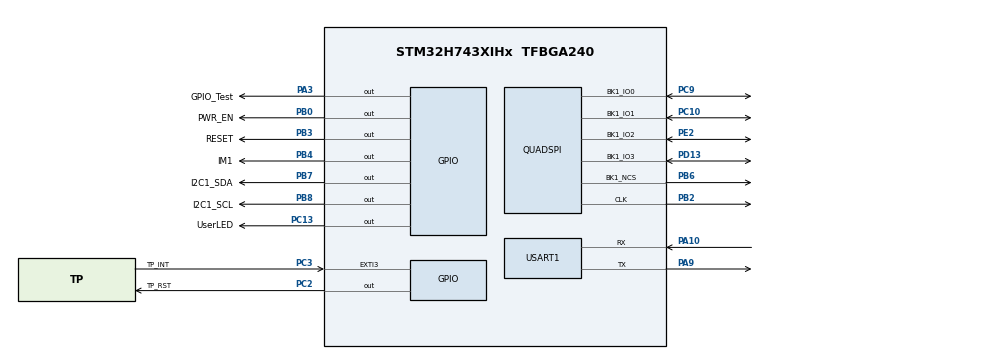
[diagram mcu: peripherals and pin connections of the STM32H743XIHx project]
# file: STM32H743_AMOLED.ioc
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CORTEX_M7.default_mode_Activation=0
Mcu.Family=STM32H7
Mcu.Name=STM32H743XIHx
Mcu.Package=TFBGA240
NVIC.PriorityGroup=NVIC_PRIORITYGROUP_4
NVIC.QUADSPI_IRQn=true\:0\:0\:false\:false\:true\:true\:true\:true
PA10.GPIO_Speed=GPIO_SPEED_FREQ_VERY_HIGH
PA10.Mode=Asynchronous
PA10.Signal=USART1_RX
PA13\ (JTMS/SWDIO).Mode=Serial_Wire
PA13\ (JTMS/SWDIO).Signal=DEBUG_JTMS-SWDIO
PA14\ (JTCK/SWCLK).Mode=Serial_Wire
PA14\ (JTCK/SWCLK).Signal=DEBUG_JTCK-SWCLK
PA3.GPIO_Label=GPIO_Test
PA3.GPIO_PuPd=GPIO_PULLDOWN
PA3.GPIO_Speed=GPIO_SPEED_FREQ_VERY_HIGH
PA3.PinState=GPIO_PIN_RESET
PA3.Signal=GPIO_Output
PA9.GPIO_Speed=GPIO_SPEED_FREQ_VERY_HIGH
PA9.Mode=Asynchronous
PA9.Signal=USART1_TX
PB0.GPIO_Label=PWR_EN
PB0.GPIO_PuPd=GPIO_PULLDOWN
PB0.GPIO_Speed=GPIO_SPEED_FREQ_VERY_HIGH
PB0.PinState=GPIO_PIN_RESET
PB0.Signal=GPIO_Output
PB2.GPIO_PuPd=GPIO_PULLUP
PB2.GPIO_Speed=GPIO_SPEED_FREQ_VERY_HIGH
PB2.Mode=Single Bank 1
PB2.Signal=QUADSPI_CLK
PB3\ (JTDO/TRACESWO).GPIO_Label=RESET
PB3\ (JTDO/TRACESWO).GPIO_PuPd=GPIO_PULLDOWN
PB3\ (JTDO/TRACESWO).GPIO_Speed=GPIO_SPEED_FREQ_VERY_HIGH
PB3\ (JTDO/TRACESWO).PinState=GPIO_PIN_RESET
PB3\ (JTDO/TRACESWO).Signal=GPIO_Output
PB4\ (NJTRST).GPIO_Label=IM1
PB4\ (NJTRST).GPIO_PuPd=GPIO_PULLUP
PB4\ (NJTRST).GPIO_Speed=GPIO_SPEED_FREQ_VERY_HIGH
PB4\ (NJTRST).PinState=GPIO_PIN_SET
PB4\ (NJTRST).Signal=GPIO_Output
PB6.GPIO_PuPd=GPIO_PULLUP
PB6.GPIO_Speed=GPIO_SPEED_FREQ_VERY_HIGH
PB6.Mode=Single Bank 1
PB6.Signal=QUADSPI_BK1_NCS
PB7.GPIO_FM7=SYSCFG_PMCR_I2C_PB7_FMP
PB7.GPIO_Label=I2C1_SDA
PB7.GPIO_ModeDefaultOutputPP=GPIO_MODE_OUTPUT_OD
PB7.GPIO_PuPd=GPIO_NOPULL
PB7.GPIO_Speed=GPIO_SPEED_FREQ_VERY_HIGH
PB7.PinState=GPIO_PIN_RESET
PB7.Signal=GPIO_Output
PB8.GPIO_FM8=SYSCFG_PMCR_I2C_PB8_FMP
PB8.GPIO_Label=I2C1_SCL
PB8.GPIO_ModeDefaultOutputPP=GPIO_MODE_OUTPUT_OD
PB8.GPIO_PuPd=GPIO_NOPULL
PB8.GPIO_Speed=GPIO_SPEED_FREQ_VERY_HIGH
PB8.PinState=GPIO_PIN_RESET
PB8.Signal=GPIO_Output
PC10.GPIO_Speed=GPIO_SPEED_FREQ_VERY_HIGH
PC10.Mode=Single Bank 1
PC10.Signal=QUADSPI_BK1_IO1
PC13.GPIO_Label=UserLED
PC13.GPIO_PuPd=GPIO_PULLUP
PC13.GPIO_Speed=GPIO_SPEED_FREQ_LOW
PC13.PinState=GPIO_PIN_SET
PC13.Signal=GPIO_Output
PC14-OSC32_IN\ (OSC32_IN).Mode=LSE-External-Oscillator
PC14-OSC32_IN\ (OSC32_IN).Signal=RCC_OSC32_IN
PC15-OSC32_OUT\ (OSC32_OUT).Mode=LSE-External-Oscillator
PC15-OSC32_OUT\ (OSC32_OUT).Signal=RCC_OSC32_OUT
PC2.GPIO_Label=TP_RST
PC2.GPIO_PuPd=GPIO_PULLDOWN
PC2.GPIO_Speed=GPIO_SPEED_FREQ_VERY_HIGH
PC2.PinState=GPIO_PIN_RESET
PC2.Signal=GPIO_Output
PC3.GPIO_Label=TP_INT
PC3.GPIO_ModeDefaultEXTI=GPIO_MODE_IT_FALLING
PC3.GPIO_PuPd=GPIO_PULLUP
PC3.Signal=GPXTI3
PC9.GPIO_Speed=GPIO_SPEED_FREQ_VERY_HIGH
PC9.Mode=Single Bank 1
PC9.Signal=QUADSPI_BK1_IO0
PD13.GPIO_Speed=GPIO_SPEED_FREQ_VERY_HIGH
PD13.Mode=Single Bank 1
PD13.Signal=QUADSPI_BK1_IO3
PE2.GPIO_Speed=GPIO_SPEED_FREQ_VERY_HIGH
PE2.Mode=Single Bank 1
PE2.Signal=QUADSPI_BK1_IO2
PH0-OSC_IN\ (PH0).Mode=HSE-External-Oscillator
PH0-OSC_IN\ (PH0).Signal=RCC_OSC_IN
PH1-OSC_OUT\ (PH1).Mode=HSE-External-Oscillator
PH1-OSC_OUT\ (PH1).Signal=RCC_OSC_OUT
ProjectManager.HeapSize=0x200
ProjectManager.StackSize=0x400
ProjectManager.TargetToolchain=MDK-ARM V5.32
QUADSPI.ClockPrescaler=4
QUADSPI.FifoThreshold=32
QUADSPI.FlashSize=22
QUADSPI.SampleShifting=QSPI_SAMPLE_SHIFTING_NONE
RCC.ADCFreq_Value=240000000
RCC.APB1Freq_Value=120000000
RCC.APB2Freq_Value=120000000
RCC.APB3Freq_Value=120000000
RCC.APB4Freq_Value=120000000
RCC.CortexFreq_Value=480000000
RCC.D1PPRE=RCC_APB3_DIV2
RCC.D2PPRE1=RCC_APB1_DIV2
RCC.D2PPRE2=RCC_APB2_DIV2
RCC.D3PPRE=RCC_APB4_DIV2
RCC.DIVM1=5
RCC.DIVM2=25
RCC.DIVM3=25
RCC.DIVN1=192
RCC.DIVN2=480
RCC.DIVN3=480
RCC.DIVR2=1
RCC.HCLKFreq_Value=240000000
RCC.HPRE=RCC_HCLK_DIV2
RCC.PLL2FRACN=0
RCC.PLL3FRACN=0
RCC.PLLFRACN=0
RCC.PLLSourceVirtual=RCC_PLLSOURCE_HSE
RCC.SYSCLKFreq_VALUE=480000000
RCC.SYSCLKSource=RCC_SYSCLKSOURCE_PLLCLK
RCC.USBFreq_Value=480000000
USART1.VirtualMode-Asynchronous=VM_ASYNC
board=custom

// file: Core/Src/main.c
/* USER CODE BEGIN Header */
/**
  ******************************************************************************
  * @file           : main.c
  * @brief          : Main program body
  ******************************************************************************
  * @attention
  *
  * Copyright (c) 2024 STMicroelectronics.
  * All rights reserved.
  *
  * This software is licensed under terms that can be found in the LICENSE file
  * in the root directory of this software component.
  * If no LICENSE file comes with this software, it is provided AS-IS.
  *
  ******************************************************************************
  */
/* USER CODE END Header */
#include "main.h"
#include "quadspi.h"
#include "usart.h"
#include "gpio.h"

/* USER CODE BEGIN Includes */
#include "amoled_driver.h"
#include "touch_driver.h"
/* USER CODE END Includes */

void SystemClock_Config(void);

int main(void)
{

  /* MCU Configuration--------------------------------------------------------*/

  /* Reset of all peripherals, Initializes the Flash interface and the Systick. */
  HAL_Init();

  /* Configure the system clock */
  SystemClock_Config();

  /* Initialize all configured peripherals */
  MX_GPIO_Init();
  MX_QUADSPI_Init();
  MX_USART1_UART_Init();
  /* USER CODE BEGIN 2 */
	delay_init(480);
	qspi_amoled_Init();
//	TP_Init();
	TP_Paint();
  /* USER CODE END 2 */

  /* Infinite loop */
  /* USER CODE BEGIN WHILE */
  while (1)
  {
    HAL_GPIO_WritePin(UserLED_GPIO_Port, UserLED_Pin, 0);
    HAL_Delay(500);
    HAL_GPIO_WritePin(UserLED_GPIO_Port, UserLED_Pin, 1);
    HAL_Delay(500);
    /* USER CODE END WHILE */

  }
}

void SystemClock_Config(void)
{
  RCC_OscInitTypeDef RCC_OscInitStruct = {0};
  RCC_ClkInitTypeDef RCC_ClkInitStruct = {0};

  /** Supply configuration update enable
  */
  HAL_PWREx_ConfigSupply(PWR_LDO_SUPPLY);

  /** Configure the main internal regulator output voltage
  */
  __HAL_PWR_VOLTAGESCALING_CONFIG(PWR_REGULATOR_VOLTAGE_SCALE1);

  while(!__HAL_PWR_GET_FLAG(PWR_FLAG_VOSRDY)) {}

  __HAL_RCC_SYSCFG_CLK_ENABLE();
  __HAL_PWR_VOLTAGESCALING_CONFIG(PWR_REGULATOR_VOLTAGE_SCALE0);

  while(!__HAL_PWR_GET_FLAG(PWR_FLAG_VOSRDY)) {}

  /** Initializes the RCC Oscillators according to the specified parameters
  * in the RCC_OscInitTypeDef structure.
  */
  RCC_OscInitStruct.OscillatorType = RCC_OSCILLATORTYPE_HSE;
  RCC_OscInitStruct.HSEState = RCC_HSE_ON;
  RCC_OscInitStruct.PLL.PLLState = RCC_PLL_ON;
  RCC_OscInitStruct.PLL.PLLSource = RCC_PLLSOURCE_HSE;
  RCC_OscInitStruct.PLL.PLLM = 5;
  RCC_OscInitStruct.PLL.PLLN = 192;
  RCC_OscInitStruct.PLL.PLLP = 2;
  RCC_OscInitStruct.PLL.PLLQ = 2;
  RCC_OscInitStruct.PLL.PLLR = 2;
  RCC_OscInitStruct.PLL.PLLRGE = RCC_PLL1VCIRANGE_2;
  RCC_OscInitStruct.PLL.PLLVCOSEL = RCC_PLL1VCOWIDE;
  RCC_OscInitStruct.PLL.PLLFRACN = 0;
  if (HAL_RCC_OscConfig(&RCC_OscInitStruct) != HAL_OK)
  {
    Error_Handler();
  }

  /** Initializes the CPU, AHB and APB buses clocks
  */
  RCC_ClkInitStruct.ClockType = RCC_CLOCKTYPE_HCLK|RCC_CLOCKTYPE_SYSCLK
                              |RCC_CLOCKTYPE_PCLK1|RCC_CLOCKTYPE_PCLK2
                              |RCC_CLOCKTYPE_D3PCLK1|RCC_CLOCKTYPE_D1PCLK1;
  RCC_ClkInitStruct.SYSCLKSource = RCC_SYSCLKSOURCE_PLLCLK;
  RCC_ClkInitStruct.SYSCLKDivider = RCC_SYSCLK_DIV1;
  RCC_ClkInitStruct.AHBCLKDivider = RCC_HCLK_DIV2;
  RCC_ClkInitStruct.APB3CLKDivider = RCC_APB3_DIV2;
  RCC_ClkInitStruct.APB1CLKDivider = RCC_APB1_DIV2;
  RCC_ClkInitStruct.APB2CLKDivider = RCC_APB2_DIV2;
  RCC_ClkInitStruct.APB4CLKDivider = RCC_APB4_DIV2;

  if (HAL_RCC_ClockConfig(&RCC_ClkInitStruct, FLASH_LATENCY_4) != HAL_OK)
  {
    Error_Handler();
  }
}

void Error_Handler(void)
{
  __disable_irq();
  while (1)
  {
  }
}
